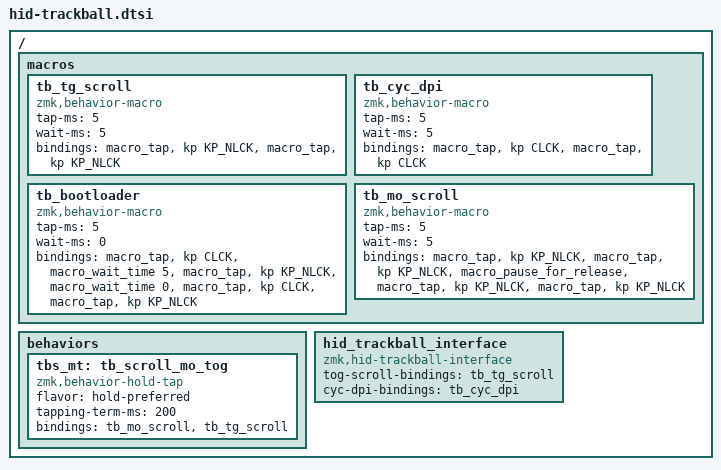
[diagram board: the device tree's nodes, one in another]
/*
 * Copyright (c) 2024 The ZMK Contributors
 *
 * SPDX-License-Identifier: MIT
 */
 
 / {
    macros {
        /omit-if-no-ref/ tb_tg_scroll: tb_tg_scroll {
            compatible = "zmk,behavior-macro";
            #binding-cells = <0>;
            tap-ms = <5>;
            wait-ms = <5>;
            bindings
                = <&macro_tap &kp KP_NLCK>
                , <&macro_tap &kp KP_NLCK>
                ;
        };

        /omit-if-no-ref/ tb_cyc_dpi: tb_cyc_dpi {
            compatible = "zmk,behavior-macro";
            #binding-cells = <0>;
            tap-ms = <5>;
            wait-ms = <5>;
            bindings
                = <&macro_tap &kp CLCK>
                , <&macro_tap &kp CLCK>
                ;
        };

        /omit-if-no-ref/ tb_bootloader: tb_bootloader {
            compatible = "zmk,behavior-macro";
            #binding-cells = <0>;
            tap-ms = <5>;
            wait-ms = <0>;
            bindings
                = <&macro_tap &kp CLCK>
                , <&macro_wait_time 5>
                , <&macro_tap &kp KP_NLCK>
                , <&macro_wait_time 0>
                , <&macro_tap &kp CLCK>
                , <&macro_tap &kp KP_NLCK>
                ;
        };

        /omit-if-no-ref/ tb_mo_scroll: tb_mo_scroll {
            compatible = "zmk,behavior-macro";
            #binding-cells = <0>;
            tap-ms = <5>;
            wait-ms = <5>;
            bindings
                = <&macro_tap &kp KP_NLCK>
                , <&macro_tap &kp KP_NLCK>
                , <&macro_pause_for_release>
                , <&macro_tap &kp KP_NLCK>
                , <&macro_tap &kp KP_NLCK>
                ;
        };
    };

    behaviors {  
        /omit-if-no-ref/ tbs_mt: tb_scroll_mo_tog {
            compatible = "zmk,behavior-hold-tap";
            #binding-cells = <2>;
            flavor = "hold-preferred";
            tapping-term-ms = <200>;
            bindings = <&tb_mo_scroll>, <&tb_tg_scroll>;
        };
    };

    hid_trackball_interface: hid_trackball_interface {
        compatible = "zmk,hid-trackball-interface";
        tog-scroll-bindings = <&tb_tg_scroll>;
        cyc-dpi-bindings = <&tb_cyc_dpi>;
    };
};
